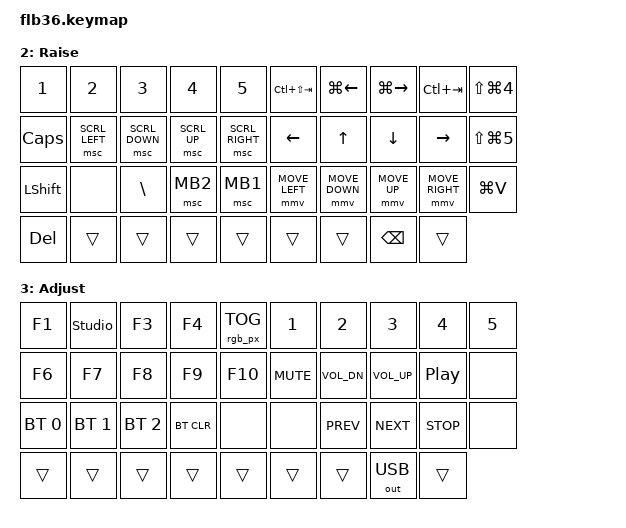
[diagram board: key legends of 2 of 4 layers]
/*
 * Copyright (c) 2026
 *
 * SPDX-License-Identifier: MIT
 *
 * Ported from FLB36
 *
 * Key positions (for combos):
 *  0- 4 Q-T    5- 9 Y-P
 * 10-14 A-G   15-19 H-;
 * 20-24 Z-B   25-29 N-/
 *     30-33 L thumb (col 1-4)   34-37 R thumb
 *
 * Encoders (see ZMK docs):
 *   - ROTATION: A/B wires to GPIO P1.15 + P0.02 (pro_micro 18/19), set in sensor-bindings.
 *   - PRESS: matrix keys (left col 4 = TG layer 2; right thumb 1 = mute), NOT the GPIO encoder.
 *
 * ZMK Studio cannot edit encoder rotation yet; change sensor-bindings in this file.
 */

#include <behaviors.dtsi>
#include <dt-bindings/zmk/keys.h>
#include <dt-bindings/zmk/bt.h>
#include <dt-bindings/zmk/pointing.h>
#include <dt-bindings/zmk/outputs.h>
#include <dt-bindings/zmk/rgb.h>

&mt {
    flavor = "tap-preferred";
    tapping-term-ms = <170>;
    quick-tap-ms = <150>;
    require-prior-idle-ms = <120>;
};

&lt {
    flavor = "hold-preferred";
    tapping-term-ms = <170>;
    quick-tap-ms = <150>;
};

/ {
    behaviors {
        rgb_px: rgb_px {
            compatible = "flb36,behavior-rgb-proxy";
            #binding-cells = <2>;
            display-name = "Peripheral Underglow";
        };
    };

    combos {
        compatible = "zmk,combos";

        combo_as_bslash {
            timeout-ms = <35>;
            require-prior-idle-ms = <120>;
            key-positions = <10 11>;
            bindings = <&kp LS(BSLH)>;
        };

        combo_rt_9 {
            timeout-ms = <35>;
            require-prior-idle-ms = <120>;
            key-positions = <3 4>;
            bindings = <&kp LPAR>;
        };

        combo_fg_lbrk {
            timeout-ms = <35>;
            require-prior-idle-ms = <120>;
            key-positions = <13 14>;
            bindings = <&kp LBKT>;
        };

        combo_vb_lbkt {
            timeout-ms = <35>;
            require-prior-idle-ms = <120>;
            key-positions = <23 24>;
            bindings = <&kp LS(LBKT)>;
        };

        combo_yu_0 {
            timeout-ms = <35>;
            require-prior-idle-ms = <120>;
            key-positions = <5 6>;
            bindings = <&kp RPAR>;
        };

        combo_hj_rbrk {
            timeout-ms = <35>;
            require-prior-idle-ms = <120>;
            key-positions = <15 16>;
            bindings = <&kp RBKT>;
        };

        combo_nm_rbkt {
            timeout-ms = <35>;
            require-prior-idle-ms = <120>;
            key-positions = <25 26>;
            bindings = <&kp LS(RBKT)>;
        };

        combo_jk_esc {
            timeout-ms = <35>;
            require-prior-idle-ms = <120>;
            key-positions = <16 17>;
            bindings = <&kp ESC>;
        };
    };

    /* Adjust: hold both thumb space keys (lower + raise layer-taps) together. */
    conditional_layers {
        compatible = "zmk,conditional-layers";
        adjust_layer {
            if-layers = <1 2>;
            then-layer = <3>;
        };
    };

    keymap {
        compatible = "zmk,keymap";

        default_layer {
            display-name = "Base";
            bindings = <
    &kp Q           &kp W           &kp E           &kp R           &kp T           &kp Y           &kp U           &kp I           &kp O           &kp P
    &kp A           &kp S           &kp D           &kp F           &kp G           &kp H           &kp J           &kp K           &kp L           &kp SEMI
    &mt LSHFT Z     &mt LALT X      &mt LCTRL C     &mt LGUI V      &kp B           &kp N           &mt RGUI M      &mt RCTRL COMMA &mt RALT DOT     &mt RSHFT FSLH
    &kp LALT        &mt LGUI TAB    &lt 1 SPACE     &tog 2          &kp C_MUTE      &lt 2 SPACE     &kp BSPC        &mt RSHFT RET
            >;

            /* Left: Tab / Shift+Tab (swap order if direction feels reversed). Right: volume. */
            sensor-bindings = <&inc_dec_kp TAB LS(TAB) &inc_dec_kp C_VOL_UP C_VOL_DN>;
        };

        lower_layer {
            display-name = "Lower";
            bindings = <
    &kp LS(N1)      &kp LS(N2)      &kp LS(N8)      &kp GRAVE       &kp LS(GRAVE)   &kp N7          &kp N8          &kp N9          &kp LS(EQUAL)   &kp SQT
    &kp LS(N3)      &kp SQT         &kp LS(SQT)     &kp MINUS       &kp EQUAL       &kp N4          &kp N5          &kp N6          &kp MINUS       &kp LS(SEMI)
    &kp LS(MINUS)   &kp LS(N4)      &kp LS(N5)      &kp LS(N6)      &kp LS(N7)      &kp N1          &kp N2          &kp N3          &kp BSLH        &kp LC(DEL)
    &trans          &trans          &trans          &trans          &trans          &kp RET         &kp N0          &kp DOT
            >;

            sensor-bindings = <&inc_dec_kp LEFT RIGHT &inc_dec_kp C_PREV C_NEXT>;
        };

        raise_layer {
            display-name = "Raise";
            bindings = <
    &kp N1          &kp N2          &kp N3          &kp N4          &kp N5          &kp LC(LS(TAB)) &kp LG(LEFT)    &kp LG(RIGHT)   &kp LC(TAB)     &kp LS(LG(N4))
    &kp CAPS        &msc SCRL_LEFT  &msc SCRL_DOWN  &msc SCRL_UP    &msc SCRL_RIGHT &kp LEFT        &kp UP          &kp DOWN        &kp RIGHT       &kp LS(LG(N5))
    &kp LSHFT       &none           &kp BSLH        &msc MB2        &msc MB1        &mmv MOVE_LEFT  &mmv MOVE_DOWN  &mmv MOVE_UP    &mmv MOVE_RIGHT &kp LG(V)
    &kp DEL         &trans          &trans          &trans          &trans          &trans          &trans          &kp BSPC        &trans
            >;

            sensor-bindings = <&inc_dec_kp DOWN UP &inc_dec_kp C_BRI_DEC C_BRI_INC>;
        };

        adjust_layer {
            display-name = "Adjust";
            bindings = <
    &kp F1          &studio_unlock  &kp F3          &kp F4          &rgb_px RGB_TOG &kp N1          &kp N2          &kp N3          &kp N4          &kp N5
    &kp F6          &kp F7          &kp F8          &kp F9          &kp F10         &kp C_MUTE      &kp C_VOL_DN    &kp C_VOL_UP    &kp C_PP        &none
    &bt BT_SEL 0    &bt BT_SEL 1    &bt BT_SEL 2    &bt BT_CLR      &none           &none           &kp C_PREV      &kp C_NEXT      &kp C_STOP      &none
    &trans          &trans          &trans          &trans          &trans          &trans          &trans          &out OUT_USB    &trans
            >;

            sensor-bindings = <&inc_dec_kp LEFT RIGHT &inc_dec_kp C_VOL_DN C_VOL_UP>;
        };
    };
};
